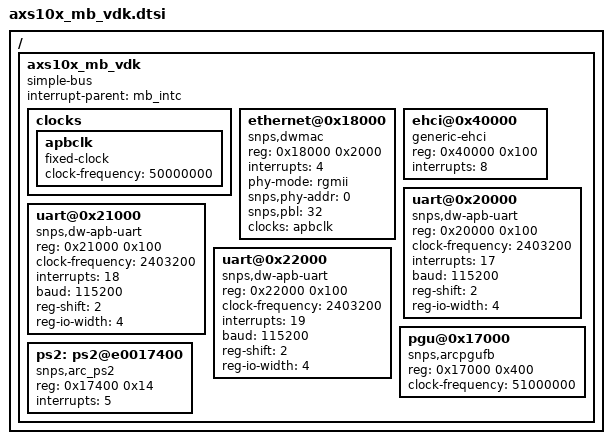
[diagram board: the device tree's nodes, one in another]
/*
 * Support for peripherals on the AXS10x mainboard (VDK version)
 *
 * Copyright (C) 2013-15 Synopsys, Inc. (www.synopsys.com)
 *
 * This program is free software; you can redistribute it and/or modify
 * it under the terms of the GNU General Public License version 2 as
 * published by the Free Software Foundation.
 */

/ {
	axs10x_mb_vdk {
		compatible = "simple-bus";
		#address-cells = <1>;
		#size-cells = <1>;
		ranges = <0x00000000 0xe0000000 0x10000000>;
		interrupt-parent = <&mb_intc>;

		clocks {
			apbclk: apbclk {
				compatible = "fixed-clock";
				clock-frequency = <50000000>;
				#clock-cells = <0>;
			};

		};

/* Not supported in VDK
		nand@0x16000 {
			compatible = "snps,axs-nand";
			reg = < 0x16000 0x200 >;
		};
*/
		ethernet@0x18000 {
			#interrupt-cells = <1>;
			compatible = "snps,dwmac";
			reg = < 0x18000 0x2000 >;
			interrupts = < 4 >;
			interrupt-names = "macirq";
			phy-mode = "rgmii";
			snps,phy-addr = < 0 >;  // VDK model phy address is 0
			snps,pbl = < 32 >;
			clocks = <&apbclk>;
			clock-names = "stmmaceth";
		};

		ehci@0x40000 {
			compatible = "generic-ehci";
			reg = < 0x40000 0x100 >;
			interrupts = < 8 >;
		};
/*
		ohci@0x60000 {
			compatible = "generic-ohci";
			reg = < 0x60000 0x100 >;
			interrupts = < 8 >;
		}; */

/* MMC not supported in VDK
		mmc@0x15000 {
			compatible = "snps,dw-mshc";
			reg = < 0x15000 0x400 >;
			num-slots = < 1 >;
			fifo-depth = < 16 >;
			card-detect-delay = < 200 >;
			clocks = <&apbclk>, <&mmcclk>;
			clock-names = "biu", "ciu";
			interrupts = < 7 >;
			bus-width = < 4 >;
		};
*/
		uart@0x20000 {
			compatible = "snps,dw-apb-uart";
			reg = <0x20000 0x100>;
			clock-frequency = <2403200>;
			interrupts = <17>;
			baud = <115200>;
			reg-shift = <2>;
			reg-io-width = <4>;
		};

		uart@0x21000 {
			compatible = "snps,dw-apb-uart";
			reg = <0x21000 0x100>;
			clock-frequency = <2403200>;
			interrupts = <18>;
			baud = <115200>;
			reg-shift = <2>;
			reg-io-width = <4>;
		};

		uart@0x22000 {
			compatible = "snps,dw-apb-uart";
			reg = <0x22000 0x100>;
			clock-frequency = <2403200>;
			interrupts = <19>;
			baud = <115200>;
			reg-shift = <2>;
			reg-io-width = <4>;
		};

/* I2C not supported in VDK
		i2c@0x1d000 {
			compatible = "snps,designware-i2c";
			reg = <0x1d000 0x100>;
			clock-frequency = <400000>;
			clocks = <&i2cclk>;
			interrupts = <14>;
		};

		i2c@0x1e000 {
			compatible = "snps,designware-i2c";
			reg = <0x1e000 0x100>;
			clock-frequency = <400000>;
			clocks = <&i2cclk>;
			interrupts = <15>;
		};

		i2c@0x1f000 {
			compatible = "snps,designware-i2c";
			#address-cells = <1>;
			#size-cells = <0>;
			reg = <0x1f000 0x100>;
			clock-frequency = <400000>;
			clocks = <&i2cclk>;
			interrupts = <16>;
*/

/* PGU output directly sent to virtual LCD screen; hdmi controller not modelled
			adv7511@0x39 {
				compatible = "adi,adv7511";
				reg = <0x39>;
				interrupts = <23>;
				adi,input-id = <0x00>;
				adi,input-style = <0x00>;
				adi,bit-justification = <0x00>;
				adi,input-color-depth = <0x3>;
				adi,sync-pulse = <0x00>;
				adi,up-conversion = <0x00>;
				adi,timing-generation-sequence = <0x00>;
				adi,vsync-polarity = <0x02>;
				adi,hsync-polarity = <0x02>;
				adi,clock-delay = <0x03>;
			};
*/

/* I2C not supported in VDK
			rtc@0x6F {
				compatible = "microchip,mcp7941x";
				reg = <0x6F>;
			};

			eeprom@0x54{
				compatible = "24c01";
				reg = <0x54>;
				pagesize = <0x8>;
			};

			eeprom@0x57{
				compatible = "24c04";
				reg = <0x57>;
				pagesize = <0x8>;
			};
		};
*/

/* GPIO not supported in VDK

		gpio0:gpio@13000 {
			compatible = "snps,dw-apb-gpio";
			reg = <0x13000 0x1000>;
			#address-cells = <1>;
			#size-cells = <0>;

			gpio0_banka: gpio-controller@0 {
				compatible = "snps,dw-apb-gpio-bank";
				gpio-controller;
				#gpio-cells = <2>;
				nr-gpio = <32>;
				bank-idx = <0>;
			};

			gpio0_bankb: gpio-controller@1 {
				compatible = "snps,dw-apb-gpio-bank";
				gpio-controller;
				#gpio-cells = <2>;
				nr-gpio = <8>;
				bank-idx = <1>;
			};

			gpio0_bankc: gpio-controller@2 {
				compatible = "snps,dw-apb-gpio-bank";
				gpio-controller;
				#gpio-cells = <2>;
				nr-gpio = <8>;
				bank-idx = <2>;
			};
		};

		gpio1:gpio@14000 {
			compatible = "snps,dw-apb-gpio";
			reg = <0x14000 0x1000>;
			#address-cells = <1>;
			#size-cells = <0>;

			gpio1_banka: gpio-controller@0 {
				compatible = "snps,dw-apb-gpio-bank";
				gpio-controller;
				#gpio-cells = <2>;
				nr-gpio = <30>;
				bank-idx = <0>;
			};

			gpio1_bankb: gpio-controller@1 {
				compatible = "snps,dw-apb-gpio-bank";
				gpio-controller;
				#gpio-cells = <2>;
				nr-gpio = <10>;
				bank-idx = <1>;
			};

			gpio1_bankc: gpio-controller@2 {
				compatible = "snps,dw-apb-gpio-bank";
				gpio-controller;
				#gpio-cells = <2>;
				nr-gpio = <8>;
				bank-idx = <2>;
			};
		};
*/

		pgu@0x17000 {
			compatible = "snps,arcpgufb";
			reg = <0x17000 0x400>;
			clock-frequency = <51000000>; /* PGU'clock is initated in init function */
			// interrupts = <5>;   PGU interrupts not used, this vector is used for ps2 below
		};

/* VDK has additional ps2 keyboard/mouse interface integrated in LCD screen model */
                ps2: ps2@e0017400 {
                        compatible = "snps,arc_ps2";
                        reg = <0x17400 0x14>;
                        interrupts = <5>;
                        interrupt-names = "arc_ps2_irq";
                };

	};
};
